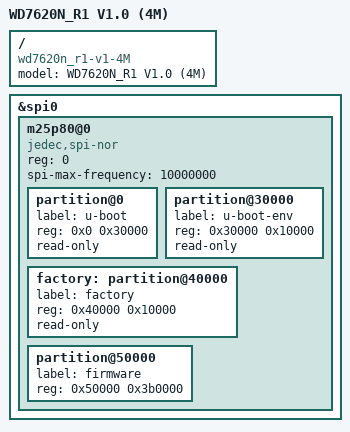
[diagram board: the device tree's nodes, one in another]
/dts-v1/;

#include "WD7620N_R1-V1.dtsi"

/ {
	compatible = "wd7620n_r1-v1-4M", "wd7620n_r1-v1", "ralink,mt7620n-soc";
	model = "WD7620N_R1 V1.0 (4M)";
};

&spi0 {
	status = "okay";

	m25p80@0 {
		#address-cells = <1>;
		#size-cells = <1>;
		compatible = "jedec,spi-nor";
		reg = <0>;
		spi-max-frequency = <10000000>;

		partition@0 {
			label = "u-boot";
			reg = <0x0 0x30000>;
			read-only;
		};

		partition@30000 {
			label = "u-boot-env";
			reg = <0x30000 0x10000>;
			read-only;
		};

		factory: partition@40000 {
			label = "factory";
			reg = <0x40000 0x10000>;
			read-only;
		};

		partition@50000 {
			label = "firmware";
			reg = <0x50000 0x3b0000>;
		};
	};
};
